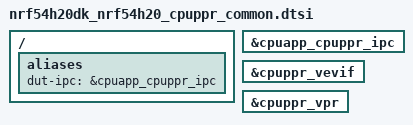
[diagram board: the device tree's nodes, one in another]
/*
 * Copyright (c) 2026 Nordic Semiconductor ASA
 *
 * SPDX-License-Identifier: Apache-2.0
 */

/ {
	aliases {
		dut-ipc = &cpuapp_cpuppr_ipc;
	};
};

&cpuapp_cpuppr_ipc {
	status = "okay";
};

&cpuppr_vevif {
	status = "okay";
};

&cpuppr_vpr {
	status = "okay";
};
